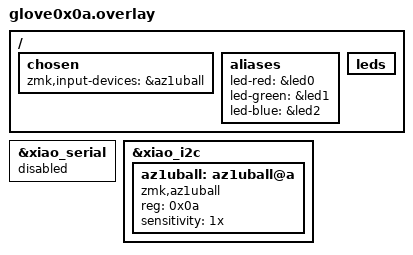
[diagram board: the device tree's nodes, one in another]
#include "glove0x0a.dtsi"
#include <dt-bindings/led/led.h>
#include <zephyr/dt-bindings/input/input-event-codes.h>

&xiao_serial {
    status = "disabled";
};

&xiao_i2c {
    az1uball: az1uball@a {
        compatible = "zmk,az1uball";
        reg = <0x0a>;
        status = "okay";
        sensitivity = "1x";
    };
};

/ {
    chosen {
        zmk,input-devices = &az1uball;
    };

    aliases {
        led-red = &led0;
        led-green = &led1;
        led-blue = &led2;
    };

    leds {
        status = "okay";
    };
};





